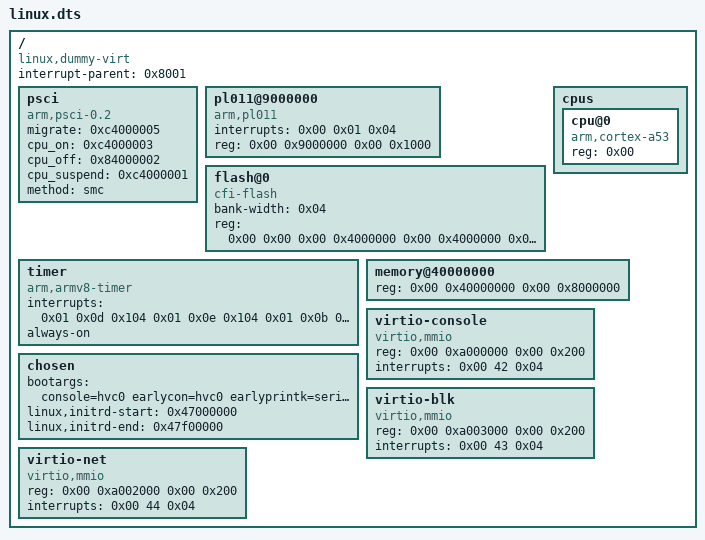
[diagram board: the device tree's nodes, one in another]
/*
 * Copyright 2025, UNSW
 *
 * SPDX-License-Identifier: BSD-2-Clause
 */

/dts-v1/;

/ {
	interrupt-parent = <0x8001>;
	#size-cells = <0x02>;
	#address-cells = <0x02>;
	compatible = "linux,dummy-virt";

	psci {
		migrate = <0xc4000005>;
		cpu_on = <0xc4000003>;
		cpu_off = <0x84000002>;
		cpu_suspend = <0xc4000001>;
		method = "smc";
		compatible = "arm,psci-0.2\0arm,psci";
	};

	pl011@9000000 {
		interrupts = <0x00 0x01 0x04>;
		reg = <0x00 0x9000000 0x00 0x1000>;
		compatible = "arm,pl011", "arm,primecell";
	};

	flash@0 {
		bank-width = <0x04>;
		reg = <0x00 0x00 0x00 0x4000000 0x00 0x4000000 0x00 0x4000000>;
		compatible = "cfi-flash";
	};

	cpus {
		#size-cells = <0x00>;
		#address-cells = <0x01>;

		cpu@0 {
			reg = <0x00>;
			compatible = "arm,cortex-a53";
			device_type = "cpu";
		};
	};

	timer {
		interrupts = <0x01 0x0d 0x104 0x01 0x0e 0x104 0x01 0x0b 0x104 0x01 0x0a 0x104>;
		always-on;
		compatible = "arm,armv8-timer\0arm,armv7-timer";
	};

    memory@40000000 {
		reg = <0x00 0x40000000 0x00 0x8000000>;
		device_type = "memory";
	};

	chosen {
		bootargs = "console=hvc0 earlycon=hvc0 earlyprintk=serial debug loglevel=8";
		linux,initrd-start = <0x47000000>;
		linux,initrd-end = <0x47f00000>;
	};

	virtio-console {
		compatible = "virtio,mmio";
		reg = <0x00 0xa000000 0x00 0x200>;
		interrupts = <0x00 42 0x04>;
	};

	virtio-blk {
		compatible = "virtio,mmio";
		reg = <0x00 0xa003000 0x00 0x200>;
		interrupts = <0x00 43 0x04>;
	};

	virtio-net {
		compatible = "virtio,mmio";
		reg = <0x00 0xa002000 0x00 0x200>;
		interrupts = <0x00 44 0x04>;
	};
};
